VERSION ""

NS_ :

BS_:

BU_:

BO_ 516 HS_CAN_204: 8 Vector__XXX
 SG_ Pedal_accel_pos_CAN_per_ : 1|10@0+ (0.1,0) [0|102] "%" Vector__XXX
 SG_ Eng_speed_CAN_rpm_ : 27|12@0+ (2,0) [0|2048] "rpm" Vector__XXX

BO_ 125 HS_CAN_7D: 8 Vector__XXX
 SG_ Pedal_brake_pos_CAN_ : 7|16@0+ (1,0) [0|65536] "" Vector__XXX

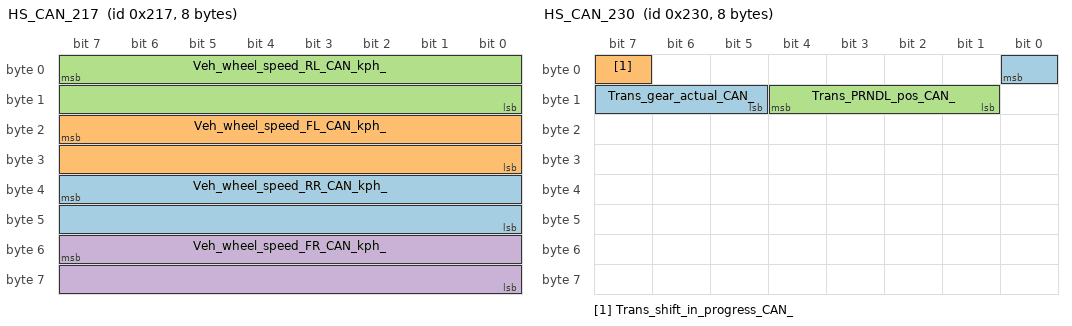
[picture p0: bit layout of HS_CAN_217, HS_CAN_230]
BO_ 535 HS_CAN_217: 8 Vector__XXX
 SG_ Veh_wheel_speed_RR_CAN_kph_ : 39|16@0+ (0.01418,0) [0|512] "kph" Vector__XXX
 SG_ Veh_wheel_speed_FL_CAN_kph_ : 23|16@0+ (0.01418,0) [0|512] "kph" Vector__XXX
 SG_ Veh_wheel_speed_RL_CAN_kph_ : 7|16@0+ (0.01418,0) [0|512] "kph" Vector__XXX
 SG_ Veh_wheel_speed_FR_CAN_kph_ : 55|16@0+ (0.01418,0) [0|512] "kph" Vector__XXX

BO_ 118 HS_CAN_76: 8 Vector__XXX
 SG_ Veh_steering_wheel_pos_CAN_ : 1|15@0+ (1,-16000) [0|16768] "" Vector__XXX

BO_ 560 HS_CAN_230: 8 Vector__XXX
 SG_ Trans_gear_actual_CAN_ : 0|4@0+ (1,1) [0|16] "" Vector__XXX
 SG_ Trans_shift_in_progress_CAN_ : 7|1@0+ (1,0) [0|1] "" Vector__XXX
 SG_ Trans_PRNDL_pos_CAN_ : 12|4@0+ (1,0) [0|16] "" Vector__XXX
